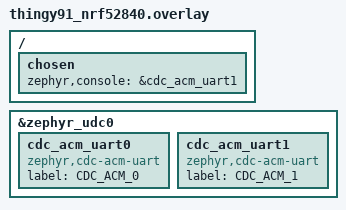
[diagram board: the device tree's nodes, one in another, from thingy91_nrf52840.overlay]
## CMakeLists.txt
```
#
# Copyright (c) 2018 Nordic Semiconductor
#
# SPDX-License-Identifier: LicenseRef-Nordic-5-Clause
#
cmake_minimum_required(VERSION 3.20.0)

find_package(Zephyr REQUIRED HINTS $ENV{ZEPHYR_BASE})
project(traffic_light_backend)

target_sources(app PRIVATE
  src/main.c
  src/events/uart_data_event.c
  src/events/module_state_event.c
  src/events/cdc_data_event.c
  src/events/ble_data_event.c
  src/events/ble_ctrl_event.c
  src/events/peer_conn_event.c
  src/events/ae_command_event.c
  src/modules/usb_cdc_handler.c
  src/modules/ae_command_handler.c
  src/modules/nus_handler.c
  src/modules/uart_handler.c
)

target_include_directories(app PRIVATE
  ${PROJECT_SOURCE_DIR}/include
)

zephyr_library_include_directories(${CMAKE_CURRENT_SOURCE_DIR})
```

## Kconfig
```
menu "Connectivity Bridge"
config BRIDGE_BUF_SIZE
	int "Transport interface buffer size"
	default 4096
	help
	  Size of transmit/receive buffer for transfer between interfaces.

config BRIDGE_UART_BUF_COUNT
	int "UART buffer block count"
	default 3
	range 3 255
	help
	  Number of buffer blocks assigned for UART instances.
	  This value is scaled with the number of interfaces.
	  With the default instance count of 2, and for example 3 buffers,
	  the total will be 6 buffers.
	  Note that all buffers are shared between UART instances.
endmenu

menu "Event Logging Options"

config LOG_MODULE_STATE_EVENT
	bool "Enable debug logging of module state events"
	default false
	help
	  Enables logging of module state events as they are produced.

config LOG_AE_CMD_EVENT
	bool "Enable debug logging of AE command events"
	default false
	help
	  Enables logging of AE command events as they are produced.

config LOG_BLE_DATA_EVENT
	bool "Enable debug logging of BLE data events"
	default false
	help
	  Enables logging of BLE data events as they are produced.

config LOG_BLE_CTRL_EVENT
	bool "Enable debug logging of BLE control events"
	default false
	help
	  Enables logging of BLE control events as they are produced.

config LOG_UART_DATA_EVENT
	bool "Enable debug logging of uart data events"
	default false
	help
	  Enables logging of UART data events as they are produced.

config LOG_PEER_CONN_EVENT
	bool "Enable debug logging of peer connection events"
	default false
	help
	  Enables logging of peer connection events.
	  
endmenu


menu "Zephyr Kernel"
source "Kconfig.zephyr"
endmenu
```

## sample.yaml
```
sample:
  description: Bluetooth Low Energy central traffic light controller
  name: BLE Traffic Light Controller
tests:
  sample.bluetooth.central_uart:
    build_only: true
    platform_allow: thingy91_nrf52840
    integration_platforms:
      - thingy91_nrf52840
    tags: bluetooth
```

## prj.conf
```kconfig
#
# Copyright (c) 2018 Nordic Semiconductor
#
# SPDX-License-Identifier: LicenseRef-Nordic-5-Clause
#

# Enable App Event Manager
CONFIG_APP_EVENT_MANAGER=y

# Enable the USB driver and USB logging
#CONFIG_CONSOLE=y
CONFIG_CONSOLE_SUBSYS=y
CONFIG_CONSOLE_GETLINE=y
CONFIG_LOG=y
CONFIG_LOG_DEFAULT_LEVEL=4
CONFIG_ASSERT=y
CONFIG_PRINTK=y
CONFIG_UART_CONSOLE=y
CONFIG_USB_DEVICE_STACK=y
CONFIG_USB_CDC_ACM=y
CONFIG_USB_DEVICE_REMOTE_WAKEUP=n
CONFIG_USB_DEVICE_MANUFACTURER="CMPEN482W"
CONFIG_USB_DEVICE_PRODUCT="Thingy:91 Traffic Light AE"
CONFIG_USB_DEVICE_VID=0x1915
CONFIG_USB_DEVICE_PID=0x9100
CONFIG_USB_DEVICE_SN="THINGY91 12PLACEHLDRS" # This is overridden at runtime
CONFIG_USB_COMPOSITE_DEVICE=y
CONFIG_USB_CDC_ACM_RINGBUF_SIZE=16384

# UART
CONFIG_UART_INTERRUPT_DRIVEN=y
CONFIG_UART_0_INTERRUPT_DRIVEN=n
CONFIG_UART_1_INTERRUPT_DRIVEN=n
CONFIG_UART_LINE_CTRL=y
CONFIG_UART_ASYNC_API=y
CONFIG_UART_0_ASYNC=y
CONFIG_UART_1_ASYNC=y
CONFIG_UART_0_NRF_HW_ASYNC=y
CONFIG_UART_1_NRF_HW_ASYNC=y
CONFIG_UART_0_NRF_HW_ASYNC_TIMER=1
CONFIG_UART_1_NRF_HW_ASYNC_TIMER=2
CONFIG_NRFX_TIMER1=y
CONFIG_NRFX_TIMER2=y
CONFIG_NRFX_PPI=y

# Enable the BLE stack with GATT Client configuration
CONFIG_BT=y
CONFIG_BT_CTLR=y
CONFIG_BT_LL_SOFTDEVICE=y
CONFIG_BT_CENTRAL=y
CONFIG_BT_AUTO_PHY_UPDATE=y
CONFIG_BT_DATA_LEN_UPDATE=y
CONFIG_BT_HCI_ACL_FLOW_CONTROL=y
CONFIG_BT_L2CAP_TX_MTU=247
CONFIG_BT_BUF_ACL_RX_SIZE=251
CONFIG_BT_GATT_CLIENT=y
CONFIG_BT_SMP=y
CONFIG_BT_SCAN_NAME_CNT=1

CONFIG_BT_CTLR_RX_BUFFERS=10
CONFIG_BT_BUF_ACL_TX_COUNT=10
CONFIG_BT_BUF_ACL_TX_SIZE=251
CONFIG_BT_CTLR_DATA_LENGTH_MAX=251

# Enable the BLE modules from NCS
CONFIG_BT_NUS_CLIENT=y
CONFIG_BT_SCAN=y
CONFIG_BT_SCAN_FILTER_ENABLE=y
CONFIG_BT_SCAN_UUID_CNT=1
CONFIG_BT_GATT_DM=y
CONFIG_HEAP_MEM_POOL_SIZE=2048

# This example requires more workqueue stack
CONFIG_SYSTEM_WORKQUEUE_STACK_SIZE=2048

# Enable bonding
CONFIG_FLASH=y
CONFIG_FLASH_PAGE_LAYOUT=y
CONFIG_FLASH_MAP=y
CONFIG_NVS=y

# Enable MCUboot
CONFIG_BOOTLOADER_MCUBOOT=y
```

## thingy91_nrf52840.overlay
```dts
/*
 * Copyright (c) 2021 Nordic Semiconductor ASA
 *
 * SPDX-License-Identifier: Apache-2.0
 */

 / {
	chosen {
			zephyr,console = &cdc_acm_uart1;
	};
};

 &zephyr_udc0 {
	cdc_acm_uart0: cdc_acm_uart0 {
		compatible = "zephyr,cdc-acm-uart";
		label = "CDC_ACM_0";
	};

	cdc_acm_uart1: cdc_acm_uart1 {
		compatible = "zephyr,cdc-acm-uart";
		label = "CDC_ACM_1";
	};
};
```

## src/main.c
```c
/*
 * Copyright (c) 2018 Nordic Semiconductor ASA
 *
 * SPDX-License-Identifier: LicenseRef-Nordic-5-Clause
 */

/** @file
 *  @brief Nordic UART Service Client sample
 */

#include <errno.h>
#include <zephyr/kernel.h>
#include <zephyr/device.h>
#include <zephyr/devicetree.h>
#include <zephyr/sys/byteorder.h>
#include <zephyr/sys/printk.h>

#include <zephyr/bluetooth/bluetooth.h>
#include <zephyr/bluetooth/hci.h>
#include <zephyr/bluetooth/conn.h>
#include <zephyr/bluetooth/uuid.h>
#include <zephyr/bluetooth/gatt.h>

#include <bluetooth/services/nus.h>
#include <bluetooth/services/nus_client.h>
#include <bluetooth/gatt_dm.h>
#include <bluetooth/scan.h>

#include <zephyr/settings/settings.h>

#include <zephyr/drivers/uart.h>
#include <zephyr/usb/usb_device.h>

#include <zephyr/logging/log.h>
#include <zephyr/console/console.h>

#include <app_event_manager.h>

#define MODULE main
#include "events/module_state_event.h"
#define LOG_MODULE_NAME main
LOG_MODULE_REGISTER(LOG_MODULE_NAME);

void main() {

	if (app_event_manager_init()) {
		LOG_ERR("Application Event Manager not initialized!");
		k_sleep(K_SECONDS(2));
		return;
	} 

	LOG_INF("Application Event Manager initialized.");
	module_set_state(MODULE_STATE_READY);
	LOG_INF("Returned from module_set_state_ready");
	k_sleep(K_SECONDS(2));
	LOG_INF("Boop from 52840!");
}
```
